# STM32MP153 register map
File version: 1.4
CPU: CM4 r0p1, little endian, no MPU, FPU, 4 interrupt priority bits
Registers are 32-bit, read-write, reset 0x0 unless marked. A register's access mark holds for its fields unless they carry their own. Offsets are from the block's base; [hi:lo] are bit positions; {n}, {i} and the like mark numbered series; 'fields as' and 'values as' point back to an identical list.

## RTC
Base 0x5C004000
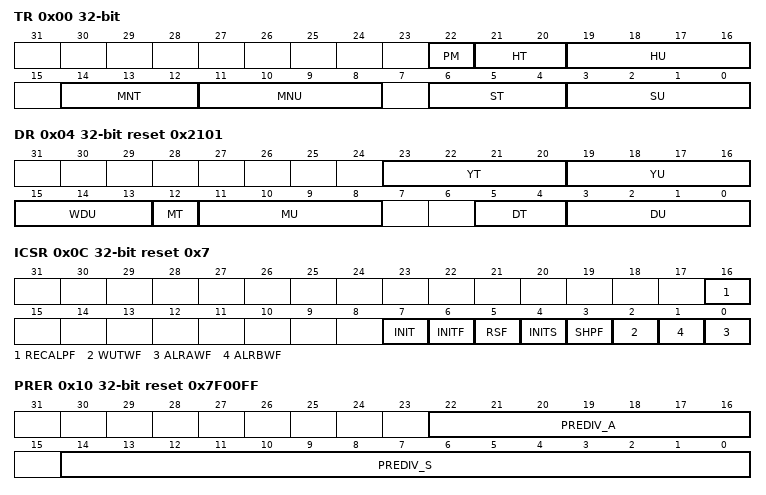
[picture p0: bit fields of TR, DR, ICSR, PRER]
0x00 TR — The RTC_TR is the calendar time shadow register. This register must be written in initialization mode only. Refer to Calendar initialization and configuration on page1830 and Reading the calendar on page1831. This register is write protected. The write access procedure is described in RTC register write protection on page1830. This register can be write-protected against non-secure access. Refer to Section50.3.4: RTC secure protection modes.
  [22] PM
    0=AM (AM or 24-hour format); 1=PM
  [21:20] HT
  [19:16] HU
  [14:12] MNT
  [11:8] MNU
  [6:4] ST
  [3:0] SU
0x04 DR reset 0x2101 — The RTC_DR is the calendar date shadow register. This register must be written in initialization mode only. Refer to Calendar initialization and configuration on page1830 and Reading the calendar on page1831. This register is write protected. The write access procedure is described in RTC register write protection on page1830. This register can be write-protected against non-secure access. Refer to Section50.3.4: RTC secure protection modes.
  [23:20] YT, [19:16] YU, [15:13] WDU range 1..7, [12] MT, [11:8] MU, [5:4] DT, [3:0] DU
0x08 SSR ro — RTC sub second register
  [15:0] SS
0x0C ICSR access per field reset 0x7 — This register is write protected. The write access procedure is described in RTC register write protection on page1830. This register can be globally protected, or each bit of this register can be individually protected against non-secure access. Refer to Section50.3.4: RTC secure protection modes.
  [16] RECALPF ro
    1=Pending (The RECALPF status flag is automatically set to 1 when software writes to the RTC_CALR register, indicating that the RTC_CALR register is blocked. When the new calibration settings are taken into account, this bit returns to 0)
  [7] INIT rw
    0=FreeRunningMode; 1=InitMode (Initialization mode used to program time and date register (RTC_TR and RTC_DR), and prescaler register (RTC_PRER). Counters are stopped and start counting from the new value when INIT is reset.)
  [6] INITF ro
    0=NotAllowed (Calendar registers update is not allowed); 1=Allowed (Calendar registers update is allowed)
  [5] RSF rw write-0-clears
    on read: 0=NotSynced (Calendar shadow registers not yet synchronized); 1=Synced (Calendar shadow registers synchronized) | on write: 0=Clear (This flag is cleared by software by writing 0)
  [4] INITS ro
    0=NotInitalized (Calendar has not been initialized); 1=Initalized (Calendar has been initialized)
  [3] SHPF ro
    0=NoShiftPending (No shift operation is pending); 1=ShiftPending (A shift operation is pending)
  [2] WUTWF ro
    0=UpdateNotAllowed (Wakeup timer configuration update not allowed); 1=UpdateAllowed (Wakeup timer configuration update allowed)
  [0] ALR{x}WF (x=A,B; step 1) ro — Alarm {x} write flag
0x10 PRER reset 0x7F00FF — This register must be written in initialization mode only. The initialization must be performed in two separate write accesses. Refer to Calendar initialization and configuration on page1830. This register is write protected. The write access procedure is described in RTC register write protection on page1830. This register can be write-protected against non-secure access. Refer to Section50.3.4: RTC secure protection modes.
  [22:16] PREDIV_A, [14:0] PREDIV_S
0x14 WUTR reset 0xFFFF — This register can be written only when WUTWF is set to 1 in RTC_ICSR. This register is write protected. The write access procedure is described in RTC register write protection on page1830. This register can be protected against non-secure access. Refer to Section50.3.4: RTC secure protection modes.
  [15:0] WUT
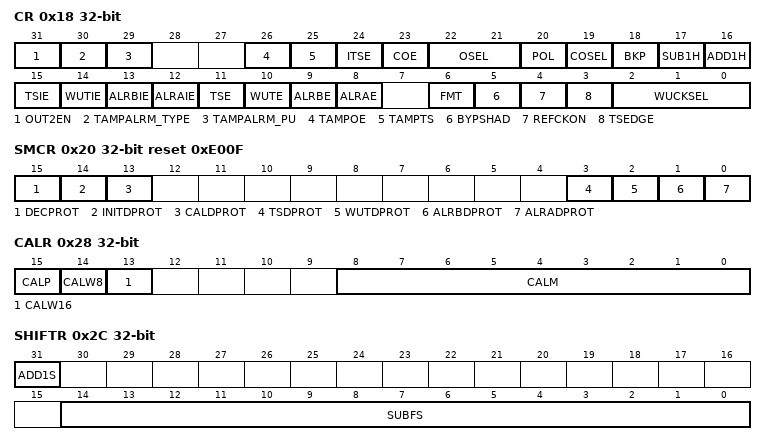
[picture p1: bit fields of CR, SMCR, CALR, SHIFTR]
0x18 CR access per field — This register is write protected. The write access procedure is described in RTC register write protection on page1830. This register can be globally protected, or each bit of this register can be individually protected against non-secure access. Refer to Section50.3.4: RTC secure protection modes.
  [31] OUT2EN rw
    0=Disabled (RTC output 2 disable); 1=Enabled (RTC output 2 enable)
  [30] TAMPALRM_TYPE rw
    0=PushPull (TAMPALRM is push-pull output); 1=OpenDrain (TAMPALRM is open-drain output)
  [29] TAMPALRM_PU rw
    0=No pull-up is applied on TAMPALRM output; 1=PullUp (A pull-up is applied on TAMPALRM output)
  [26] TAMPOE rw
    0=Disabled (The tamper flag is not routed on TAMPALRM); 1=Enabled (The tamper flag is routed on TAMPALRM, combined with the signal provided by OSEL and with the polarity provided by POL)
  [25] TAMPTS rw
    0=Disabled (Tamper detection event does not cause a RTC timestamp to be saved); 1=Enabled (Save RTC timestamp on tamper detection event)
  [24] ITSE rw
    0=Disabled (Internal event timestamp disabled); 1=Enabled (Internal event timestamp enabled)
  [23] COE rw
    0=Disabled (Calibration output disabled); 1=Enabled (Calibration output enabled)
  [22:21] OSEL rw
    0=Disabled (Output disabled); 1=Alarm A output enabled; 2=Alarm B output enabled; 3=Wakeup output enabled
  [20] POL rw
    0=High (The pin is high when ALRAF/ALRBF/WUTF is asserted (depending on OSEL[1:0])); 1=Low (The pin is low when ALRAF/ALRBF/WUTF is asserted (depending on OSEL[1:0]))
  [19] COSEL rw
    0=CalFreq_512Hz (Calibration output is 512 Hz (with default prescaler setting)); 1=CalFreq_1Hz (Calibration output is 1 Hz (with default prescaler setting))
  [18] BKP rw
    0=DSTNotChanged (Daylight Saving Time change has not been performed); 1=DSTChanged (Daylight Saving Time change has been performed)
  [17] SUB1H wo
    1=Sub1 (Subtracts 1 hour to the current time. This can be used for winter time change outside initialization mode)
  [16] ADD1H wo
    1=Add1 (Adds 1 hour to the current time. This can be used for summer time change outside initialization mode)
  [15] TSIE rw
    0=Disabled (Time-stamp Interrupt disabled); 1=Enabled (Time-stamp Interrupt enabled)
  [14] WUTIE rw
    0=Disabled (Wakeup timer interrupt disabled); 1=Enabled (Wakeup timer interrupt enabled)
  [12] ALR{x}IE (x=A,B; step 1) rw — Alarm {x} interrupt enable
    0=Disabled (Alarm Interrupt disabled); 1=Enabled (Alarm Interrupt enabled)
  [11] TSE rw
    0=Disabled (Timestamp disabled); 1=Enabled (Timestamp enabled)
  [10] WUTE rw
    0=Disabled (Wakeup timer disabled); 1=Enabled (Wakeup timer enabled)
  [8] ALR{x}E (x=A,B; step 1) rw — Alarm {x} enable
    0=Disabled (Alarm disabled); 1=Enabled (Alarm enabled)
  [6] FMT rw
    0=TwentyFourHour (24 hour/day format); 1=AM/PM hour format
  [5] BYPSHAD rw
    0=ShadowReg (Calendar values (when reading from RTC_SSR, RTC_TR, and RTC_DR) are taken from the shadow registers, which are updated once every two RTCCLK cycles); 1=BypassShadowReg (Calendar values (when reading from RTC_SSR, RTC_TR, and RTC_DR) are taken directly from the calendar counters)
  [4] REFCKON rw
    0=Disabled (RTC_REFIN detection disabled); 1=Enabled (RTC_REFIN detection enabled)
  [3] TSEDGE rw
    0=RisingEdge (RTC_TS input rising edge generates a time-stamp event); 1=FallingEdge (RTC_TS input falling edge generates a time-stamp event)
  [2:0] WUCKSEL rw
    0=Div16 (RTC/16 clock is selected); 1=Div8 (RTC/8 clock is selected); 2=Div4 (RTC/4 clock is selected); 3=Div2 (RTC/2 clock is selected); 4=ClockSpare (ck_spre (usually 1 Hz) clock is selected); 6=ClockSpareWithOffset (ck_spre (usually 1 Hz) clock is selected and 2^16 is added to the WUT counter value)
0x20 SMCR reset 0xE00F — This register can be written only when the APB access is secure.
  [15] DECPROT, [14] INITDPROT, [13] CALDPROT, [3] TSDPROT, [2] WUTDPROT, [1] ALRBDPROT, [0] ALRADPROT
0x24 WPR wo — RTC write protection register
  [7:0] KEY
    0=Activate write protection (any value that is not the keys); 83=Deactivate2 (Key 2); 202=Deactivate1 (Key 1)
0x28 CALR — This register is write protected. The write access procedure is described in RTC register write protection on page1830. This register can be write-protected against non-secure access. Refer to Section50.3.4: RTC secure protection modes.
  [15] CALP
    0=NoChange (No RTCCLK pulses are added); 1=IncreaseFreq (One RTCCLK pulse is effectively inserted every 2^11 pulses (frequency increased by 488.5 ppm))
  [14] CALW8
    1=EightSeconds (When CALW8 is set to ‘1’, the 8-second calibration cycle period is selected)
  [13] CALW16
    1=SixteenSeconds (When CALW16 is set to ‘1’, the 16-second calibration cycle period is selected.This bit must not be set to ‘1’ if CALW8=1)
  [8:0] CALM
0x2C SHIFTR wo — This register is write protected. The write access procedure is described in RTC register write protection on page1830. This register can be protected against non-secure access. Refer to Section50.3.4: RTC secure protection modes.
  [31] ADD1S
    1=Add1 (Add one second to the clock/calendar)
  [14:0] SUBFS
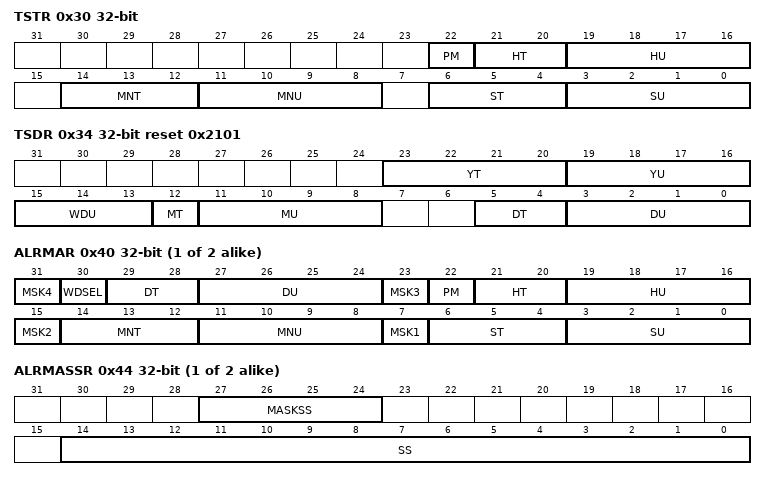
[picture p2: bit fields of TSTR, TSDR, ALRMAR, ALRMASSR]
0x30 TSTR — The content of this register is valid only when TSF is set to 1 in RTC_SR. It is cleared when TSF bit is reset. This register can be protected against non-secure access. Refer to Section50.3.4: RTC secure protection modes.
  fields as TR
0x34 TSDR reset 0x2101 — The content of this register is valid only when TSF is set to 1 in RTC_SR. It is cleared when TSF bit is reset. This register can be protected against non-secure access. Refer to Section50.3.4: RTC secure protection modes.
  fields as DR
0x38 TSSSR ro — The content of this register is valid only when TSF is set to 1 in RTC_SR. It is cleared when the TSF bit is reset. This register can be protected against non-secure access. Refer to Section50.3.4: RTC secure protection modes.
  [15:0] SS
0x40 ALRM{x}R (x=A,B; step 0x8) — Alarm {x} register
  [31] MSK4 — Alarm date mask
    0=Mask (Alarm set if the date/day match); 1=NotMask (Date/day don’t care in Alarm comparison)
  [30] WDSEL
    0=DateUnits (DU[3:0] represents the date units); 1=WeekDay (DU[3:0] represents the week day. DT[1:0] is don’t care.)
  [29:28] DT — Date tens in BCD format
  [27:24] DU — Date units or day in BCD format
  [23] MSK3 — Alarm hours mask
    values as MSK4
  [22] PM
    0=AM (AM or 24-hour format); 1=PM
  [21:20] HT — Hour tens in BCD format
  [19:16] HU — Hour units in BCD format
  [15] MSK2 — Alarm minutes mask
    values as MSK4
  [14:12] MNT — Minute tens in BCD format
  [11:8] MNU — Minute units in BCD format
  [7] MSK1 — Alarm seconds mask
    values as MSK4
  [6:4] ST — Second tens in BCD format
  [3:0] SU — Second units in BCD format
0x44 ALRM{x}SSR (x=A,B; step 0x8) — Alarm {x} sub-second register
  [27:24] MASKSS, [14:0] SS
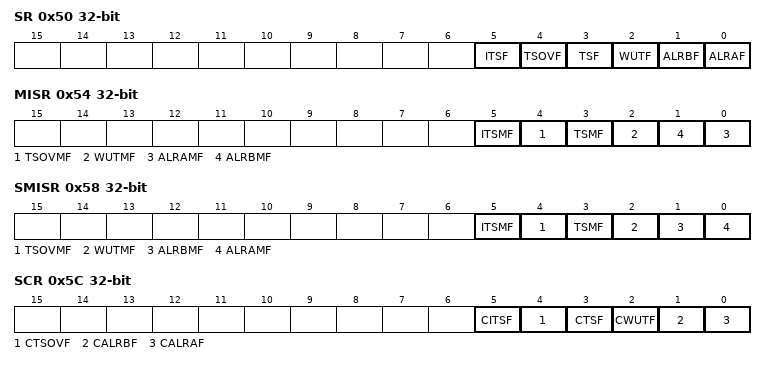
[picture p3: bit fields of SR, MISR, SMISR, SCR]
0x50 SR ro — This register can be protected against non-secure access. Refer to Section50.3.4: RTC secure protection modes.
  [5] ITSF
    1=TimestampEvent (This flag is set by hardware when a timestamp on the internal event occurs)
  [4] TSOVF
    1=Overflow (This flag is set by hardware when a time-stamp event occurs while TSF is already set)
  [3] TSF
    1=TimestampEvent (This flag is set by hardware when a time-stamp event occurs)
  [2] WUTF
    1=Zero (This flag is set by hardware when the wakeup auto-reload counter reaches 0)
  [0] ALR{x}F (x=A,B; step 1) — Alarm {x} flag
    1=Match (This flag is set by hardware when the time/date registers (RTC_TR and RTC_DR) match the Alarm register (RTC_ALRxBR))
0x54 MISR ro — RTC non-secure masked interrupt status register
  [5] ITSMF
    values as SR.ITSF
  [4] TSOVMF
    values as SR.TSOVF
  [3] TSMF
    values as SR.TSF
  [2] WUTMF
    values as SR.WUTF
  [0] ALR{x}MF (x=A,B; step 1) — Alarm {x} masked flag
    1=Match (This flag is set by hardware when the time/date registers (RTC_TR and RTC_DR) match the Alarm register (RTC_ALRMxR))
0x58 SMISR ro — This register can be protected against non-secure access. Refer to Section50.3.4: RTC secure protection modes.
  [5] ITSMF, [4] TSOVMF, [3] TSMF, [2] WUTMF, [1] ALRBMF, [0] ALRAMF
0x5C SCR wo — This register can be protected against non-secure access. Refer to Section50.3.4: RTC secure protection modes.
  [all] fields
    1=Clear interrupt flag
  [5] CITSF
  [4] CTSOVF
  [3] CTSF
  [2] CWUTF
  [1] CALRBF
  [0] CALRAF
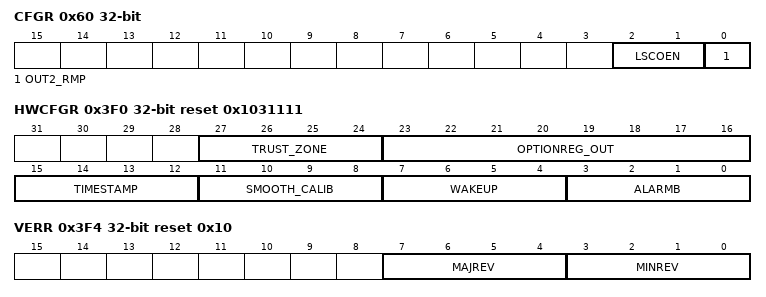
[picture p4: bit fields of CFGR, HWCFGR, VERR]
0x60 CFGR — RTC configuration register
  [2:1] LSCOEN, [0] OUT2_RMP
0x3F0 HWCFGR ro reset 0x1031111 — RTC hardware configuration register
  [27:24] TRUST_ZONE, [23:16] OPTIONREG_OUT, [15:12] TIMESTAMP, [11:8] SMOOTH_CALIB, [7:4] WAKEUP, [3:0] ALARMB
0x3F4 VERR ro reset 0x10 — RTC version register
  [7:4] MAJREV, [3:0] MINREV
0x3F8 IPIDR ro reset 0x120033 — RTC identification register
  [31:0] ID
0x3FC SIDR ro reset 0xA3C5DD01 — RTC size identification register
  [31:0] SID
